# STM32G564 register map
File version: 2.0.0
CPU: CM33 r0p4, little endian, MPU, FPU, 4 interrupt priority bits
Registers are 32-bit, read-write, reset 0x0 unless marked. A register's access mark holds for its fields unless they carry their own. Offsets are from the block's base; [hi:lo] are bit positions; {n}, {i} and the like mark numbered series.

## COMP1 — COMP address block description
Base 0x44008400
Same registers: COMP2 0x44008800, COMP3 0x44008C00, COMP4 0x44009000, COMP5 0x44009400, COMP6 0x44009800, COMP7 0x44009C00, COMP8 0x4400A000, COMP{n}_S {0x54008000+0x400*n} (n=1..8)
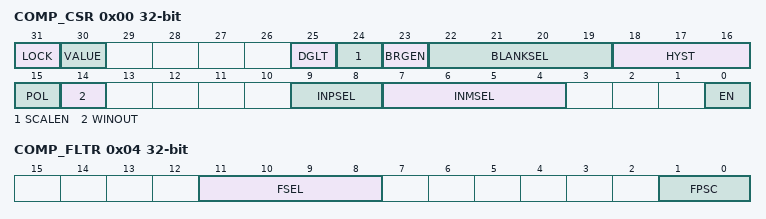
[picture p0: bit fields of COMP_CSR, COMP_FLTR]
0x00 COMP_CSR — Comparator configuration register
  [31] LOCK
    0=COMP_CxCR[31:0] and COMPx_FLTR[31:0] registers are read/write; 1=COMP_CxCR1[31:0] and COMPx_FLTR[31:0] are locked
  [30] VALUE ro — COMPx output value
  [25] DGLT — DEGLITCHER enable
    0=Disable; 1=Enable
  [24] SCALEN — VREFINT scaler enable
    0=Disable; 1=Enable
  [23] BRGEN — VREFINT scaler resistor bridge enable
    0=Disable; 1=Enable
  [22:19] BLANKSEL — Comparator x blanking signal select
  [18:16] HYST — Comparator x hysteresis
    0=No hysteresis; 1=10 mV hysteresis; 2=20 mv hysteresis; 3=30 mV hysteresis; 4=40 mV hysteresis; 5=50 mV hysteresis; 6=60 mV hysteresis; 7=70 mV hysteresis
  [15] POL — Comparator x polarity
    0=Non-inverted; 1=Inverted
  [14] WINOUT — COMPx output selector
    0=compless thansub>xless than/sub>_out = compless thansub>xless than/sub>_value; 1=compless thansub>xless than/sub>_out = WINOUT(compless thansub>xless than/sub>)
  [9:8] INPSEL — COMPx channel non-inverting input selection
  [7:4] INMSEL — COMPx channel inverting input selection
  [0] EN — COMPx channel enable
    0=Disable; 1=Enable
0x04 COMP_FLTR — Comparator filter configuration register
  [11:8] FSEL — COMPx digital filter configuration selection
    0=Filter disabled; 1=filter_sampling = comp_pclk, N = 2; 2=filter_sampling = comp_pclk, N = 4; 3=filter_sampling = comp_pclk, N = 8; 4=filter_sampling = filter_clk/2, N = 6; 5=filter_sampling = filter_clk/2, N = 8; 6=filter_sampling = filter_clk/4, N = 6; 7=filter_sampling = filter_clk/4, N = 8; 8=filter_sampling = filter_clk/8, N = 6; 9=filter_sampling = filter_clk/8, N = 8; 10=filter_sampling = filter_clk/16, N = 5; 11=filter_sampling = filter_clk/16, N = 6; 12=filter_sampling = filter_clk/16, N = 8; 13=filter_sampling = filter_clk/32, N = 5; 14=filter_sampling = filter_clk/32, N = 6; 15=filter_sampling = filter_clk/32, N = 8
  [1:0] FPSC — COMPx digital filter configuration selection
    0=filter_clk = comp_pclk; 1=filter_clk = comp_pclk/2; 2=filter_clk = comp_pclk/4; 3=filter_clk = comp_pclk/8

## CORDIC1 — CORDIC register block
Base 0x40023800
Same registers: CORDIC1_S 0x50023800
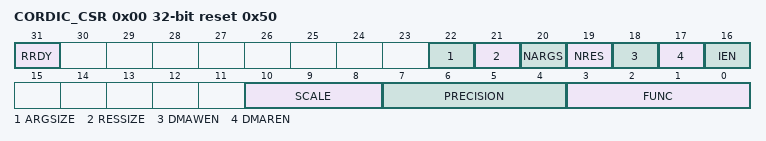
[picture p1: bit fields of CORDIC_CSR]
0x00 CORDIC_CSR reset 0x50 — CORDIC control/status register
  [31] RRDY ro — Result ready flag
    0=No new data in output register; 1=CORDIC_RDATA register contains new data
  [22] ARGSIZE — Width of input data
    0=32-bit; 1=16-bit
  [21] RESSIZE — Width of output data
    0=32-bit; 1=16-bit
  [20] NARGS — Number of arguments expected by the CORDIC_WDATA register
    0=Only one 32-bit write (or two 16-bit values if ARGSIZE = 1) is needed for the next calculation; 1=Two 32-bit values must be written to the CORDIC_WDATA register to trigger the next calculation
  [19] NRES — Number of results in the CORDIC_RDATA register
    0=Only one 32-bit value (or two 16-bit values if RESSIZE = 1) is transferred to the CORDIC_RDATA register on completion of the next calculation. One read from CORDIC_RDATA resets the RRDY flag.; 1=Two 32-bit values are transferred to the CORDIC_RDATA register on completion of the next calculation. Two reads from CORDIC_RDATA are necessary to reset the RRDY flag.
  [18] DMAWEN — Enable DMA write channel
    0=Disabled. No DMA write requests are generated.; 1=Enabled. Requests are generated on the DMA write channel whenever no operation is pending
  [17] DMAREN — Enable DMA read channel
    0=Disabled. No DMA read requests are generated.; 1=Enabled. Requests are generated on the DMA read channel whenever the RRDY flag is set.
  [16] IEN — Enable interrupt.
    0=Disabled. No interrupt requests are generated.; 1=Enabled. An interrupt request is generated whenever the RRDY flag is set.
  [10:8] SCALE — Scaling factor
  [7:4] PRECISION — Precision required (number of iterations)
  [3:0] FUNC — Function
    0=Cosine; 1=Sine
0x04 CORDIC_WDATA wo reset not defined — CORDIC argument register
  [31:0] ARG — Function input arguments
0x08 CORDIC_RDATA ro — CORDIC result register
  [31:0] RES — Function result
